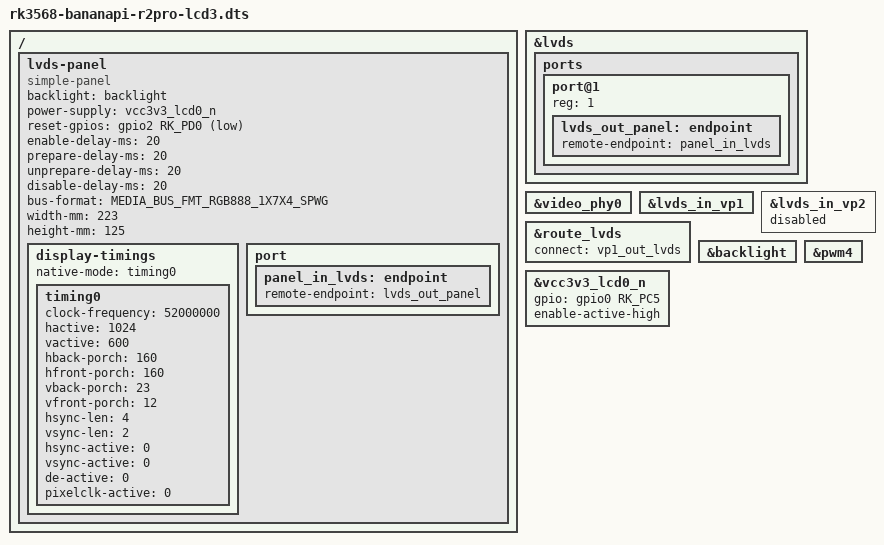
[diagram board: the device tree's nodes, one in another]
// SPDX-License-Identifier: (GPL-2.0+ OR MIT)
/*
 * Copyright (c) 2020 Rockchip Electronics Co., Ltd.
 *
 * 1024x600 lvds vp1 + hdmi vp0
 */

/dts-v1/;

#include <dt-bindings/display/media-bus-format.h>
#include <dt-bindings/gpio/gpio.h>
#include <dt-bindings/pinctrl/rockchip.h>
#include "rk3568-bananapi-r2pro.dts"

/ {
	lvds-panel {
		compatible = "simple-panel";
		backlight = <&backlight>;
		power-supply = <&vcc3v3_lcd0_n>;
		reset-gpios = <&gpio2 RK_PD0 GPIO_ACTIVE_LOW>;
		enable-delay-ms = <20>;
		prepare-delay-ms = <20>;
		unprepare-delay-ms = <20>;
		disable-delay-ms = <20>;
		bus-format = <MEDIA_BUS_FMT_RGB888_1X7X4_SPWG>;
		width-mm = <223>;
		height-mm = <125>;

		display-timings {
			native-mode = <&timing0>;

			timing0: timing0 {
				clock-frequency = <52000000>;
				hactive = <1024>;
				vactive = <600>;
				hback-porch = <160>;
				hfront-porch = <160>;
				vback-porch = <23>;
				vfront-porch = <12>;
				hsync-len = <4>;
				vsync-len = <2>;
				hsync-active = <0>;
				vsync-active = <0>;
				de-active = <0>;
				pixelclk-active = <0>;
			};
		};

		port {
			panel_in_lvds: endpoint {
				remote-endpoint = <&lvds_out_panel>;
			};
		};
	};
};

&lvds {
	status = "okay";

	ports {
		port@1 {
			reg = <1>;

			lvds_out_panel: endpoint {
				remote-endpoint = <&panel_in_lvds>;
			};
		};
	};
};

/* lvds enable phy0 */
&video_phy0 {
	status = "okay";
};

&lvds_in_vp1 {
	status = "okay";
};

&lvds_in_vp2 {
	status = "disabled";
};

&route_lvds {
	status = "okay";
	connect = <&vp1_out_lvds>;
};

&backlight {
	status = "okay";
};

&vcc3v3_lcd0_n {
	status = "okay";
	gpio = <&gpio0 RK_PC5 GPIO_ACTIVE_HIGH>;
	enable-active-high;
};

/* backlight for panel0 */
&pwm4 {
	status = "okay";
};
